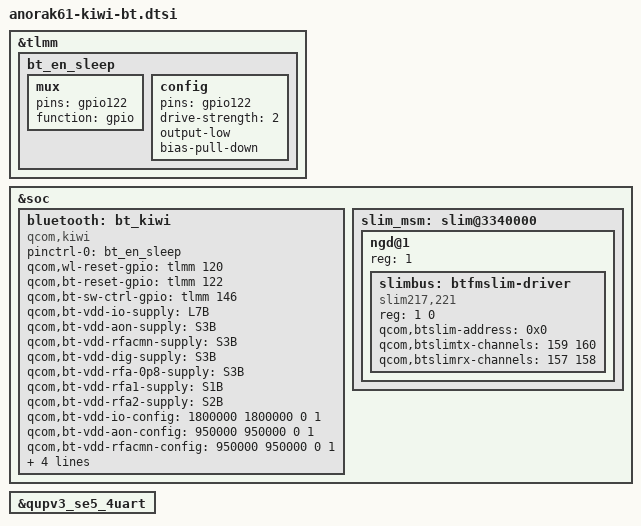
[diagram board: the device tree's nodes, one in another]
#include <dt-bindings/interconnect/qcom,pineapple.h>

&tlmm {
        bt_en_sleep: bt_en_sleep {
                mux {
                        pins = "gpio122";
                        function = "gpio";
                };

                config {
                        pins = "gpio122";
                        drive-strength = <2>;
                        output-low;
                        bias-pull-down;
                };
        };
};


&soc {
	bluetooth: bt_kiwi {
		compatible = "qcom,kiwi";
		pinctrl-names = "default";
		pinctrl-0 = <&bt_en_sleep>;
		qcom,wl-reset-gpio = <&tlmm 120 0>; /* WL_CTRL */
		qcom,bt-reset-gpio = <&tlmm 122 0>; /* BT_EN */
		qcom,bt-sw-ctrl-gpio = <&tlmm 146 0>; /* SW_CTRL */

		qcom,bt-vdd-io-supply     = <&L7B>; /* BT VDD1.8 AON */
		qcom,bt-vdd-aon-supply    = <&S3B>; /* BT AON LDO*/
		qcom,bt-vdd-rfacmn-supply = <&S3B>;
		qcom,bt-vdd-dig-supply    = <&S3B>; /* BT LDO*/
		qcom,bt-vdd-rfa-0p8-supply = <&S3B>; /* BT RFA0p8 CMN LDO*/
		qcom,bt-vdd-rfa1-supply   = <&S1B>; /* BT RFA1.8 LDO */
		qcom,bt-vdd-rfa2-supply   = <&S2B>; /* BT RFA1.2 LDO */

		qcom,bt-vdd-io-config  = <1800000 1800000 0 1>;
		qcom,bt-vdd-aon-config = <950000 950000 0 1>;
		qcom,bt-vdd-rfacmn-config = <950000 950000 0 1>;
		qcom,bt-vdd-dig-config = <950000 950000 0 1>;
		qcom,bt-vdd-rfa-0p8-config  = <950000 950000 0 1>;
		qcom,bt-vdd-rfa1-config = <1900000 1900000 0 1>;
		qcom,bt-vdd-rfa2-config = <1350000 1350000 0 1>;
	};

	slim_msm: slim@3340000 {
		status =  "ok";
		ngd@1 {
			reg = <1>;
			#address-cells = <1>;
			#size-cells = <1>;
			//slimbus child nodes
			slimbus: btfmslim-driver {
				compatible = "slim217,221";
				reg = <1 0>;
				qcom,btslim-address  = <0x0>; /* BT SLIM EP address*/
				qcom,btslimtx-channels = <159 160>; /* slimbus FM_Tx, SCO_Tx channels */
				qcom,btslimrx-channels = <157 158>; /* slimbus SCO_A2DP_Rx A2DP_Rx */
			};
		};
	};
};

//uart instance
&qupv3_se5_4uart {
	status = "ok";
};
